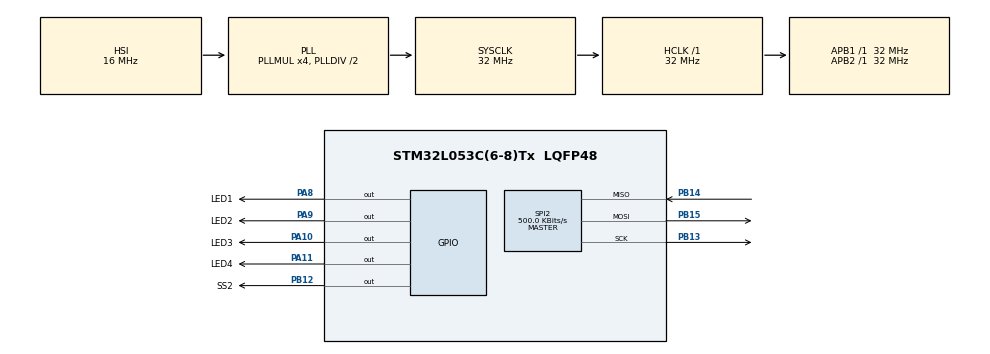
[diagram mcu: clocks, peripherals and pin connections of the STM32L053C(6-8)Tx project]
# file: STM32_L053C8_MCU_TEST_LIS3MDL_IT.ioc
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Dma.Request0=SPI2_RX
Dma.Request1=SPI2_TX
Dma.SPI2_RX.0.Direction=DMA_PERIPH_TO_MEMORY
Dma.SPI2_RX.0.Instance=DMA1_Channel4
Dma.SPI2_RX.0.MemDataAlignment=DMA_MDATAALIGN_BYTE
Dma.SPI2_RX.0.MemInc=DMA_MINC_ENABLE
Dma.SPI2_RX.0.Mode=DMA_NORMAL
Dma.SPI2_RX.0.PeriphDataAlignment=DMA_PDATAALIGN_BYTE
Dma.SPI2_RX.0.PeriphInc=DMA_PINC_DISABLE
Dma.SPI2_RX.0.Priority=DMA_PRIORITY_LOW
Dma.SPI2_TX.1.Direction=DMA_MEMORY_TO_PERIPH
Dma.SPI2_TX.1.Instance=DMA1_Channel5
Dma.SPI2_TX.1.MemDataAlignment=DMA_MDATAALIGN_BYTE
Dma.SPI2_TX.1.MemInc=DMA_MINC_ENABLE
Dma.SPI2_TX.1.Mode=DMA_NORMAL
Dma.SPI2_TX.1.PeriphDataAlignment=DMA_PDATAALIGN_BYTE
Dma.SPI2_TX.1.PeriphInc=DMA_PINC_DISABLE
Dma.SPI2_TX.1.Priority=DMA_PRIORITY_LOW
Mcu.Family=STM32L0
Mcu.Name=STM32L053C(6-8)Tx
Mcu.Package=LQFP48
NVIC.DMA1_Channel4_5_6_7_IRQn=true\:0\:0\:false\:false\:true\:false\:true\:true
NVIC.SPI2_IRQn=true\:0\:0\:true\:false\:true\:true\:true\:true
NVIC.TIM6_DAC_IRQn=true\:0\:0\:false\:false\:true\:true\:true\:true
PA10.GPIO_Label=LED3
PA10.Signal=GPIO_Output
PA11.GPIO_Label=LED4
PA11.Signal=GPIO_Output
PA13.Mode=Serial_Wire
PA13.Signal=SYS_SWDIO
PA14.Mode=Serial_Wire
PA14.Signal=SYS_SWCLK
PA8.GPIO_Label=LED1
PA8.Signal=GPIO_Output
PA9.GPIO_Label=LED2
PA9.Signal=GPIO_Output
PB12.GPIO_Label=SS2
PB12.Signal=GPIO_Output
PB13.GPIO_PuPd=GPIO_NOPULL
PB13.Mode=Full_Duplex_Master
PB13.Signal=SPI2_SCK
PB14.GPIO_PuPd=GPIO_NOPULL
PB14.Mode=Full_Duplex_Master
PB14.Signal=SPI2_MISO
PB15.GPIO_PuPd=GPIO_NOPULL
PB15.Mode=Full_Duplex_Master
PB15.Signal=SPI2_MOSI
ProjectManager.HeapSize=0x200
ProjectManager.StackSize=0x400
ProjectManager.TargetToolchain=STM32CubeIDE
RCC.AHBFreq_Value=32000000
RCC.APB1Freq_Value=32000000
RCC.APB1TimFreq_Value=32000000
RCC.APB2Freq_Value=32000000
RCC.APB2TimFreq_Value=32000000
RCC.HCLKFreq_Value=32000000
RCC.HSE_VALUE=8000000
RCC.HSI16_VALUE=16000000
RCC.HSI48_VALUE=48000000
RCC.HSI_VALUE=16000000
RCC.LSE_VALUE=32768
RCC.MSI_VALUE=2097000
RCC.PLLMUL=RCC_PLLMUL_4
RCC.SYSCLKFreq_VALUE=32000000
RCC.SYSCLKSource=RCC_SYSCLKSOURCE_PLLCLK
RCC.VCOOutputFreq_Value=64000000
SPI2.BaudRatePrescaler=SPI_BAUDRATEPRESCALER_64
SPI2.CLKPhase=SPI_PHASE_2EDGE
SPI2.CLKPolarity=SPI_POLARITY_HIGH
SPI2.CalculateBaudRate=500.0 KBits/s
SPI2.DataSize=SPI_DATASIZE_8BIT
SPI2.Direction=SPI_DIRECTION_2LINES
SPI2.Mode=SPI_MODE_MASTER
SPI2.VirtualType=VM_MASTER
TIM6.AutoReloadPreload=TIM_AUTORELOAD_PRELOAD_ENABLE
TIM6.Period=99
TIM6.Prescaler=32
VP_SYS_V_PVD_IN.Mode=Mode_PVD_Int
VP_TIM6_VS_ClockSourceINT.Mode=Enable_Timer
board=custom

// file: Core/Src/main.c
/* USER CODE BEGIN Header */
/**
 ******************************************************************************
 * @file           : main.c
 * @brief          : Main program body
 ******************************************************************************
 * @attention
 *
 * <h2><center>&copy; Copyright (c) 2023 STMicroelectronics.
 * All rights reserved.</center></h2>
 *
 * This software component is licensed by ST under BSD 3-Clause license,
 * the "License"; You may not use this file except in compliance with the
 * License. You may obtain a copy of the License at:
 *                        opensource.org/licenses/BSD-3-Clause
 *
 ******************************************************************************
 */
/* USER CODE END Header */
#include "main.h"

/* USER CODE BEGIN Includes */

#include "User/driver_lis3mdl.h"

/* USER CODE END Includes */

SPI_HandleTypeDef hspi2;
DMA_HandleTypeDef hdma_spi2_rx;
DMA_HandleTypeDef hdma_spi2_tx;

TIM_HandleTypeDef htim6;

/* USER CODE BEGIN PV */
sDriverLis3mdl_SensorData_t mag_sensor_data = { 0 };
/* USER CODE END PV */

void SystemClock_Config(void);
static void MX_GPIO_Init(void);
static void MX_DMA_Init(void);
static void MX_SPI2_Init(void);
static void MX_TIM6_Init(void);

int main(void) {

	/* MCU Configuration--------------------------------------------------------*/

	/* Reset of all peripherals, Initializes the Flash interface and the Systick. */
	HAL_Init();

	/* Configure the system clock */
	SystemClock_Config();

	/* Initialize all configured peripherals */
	MX_GPIO_Init();
	MX_DMA_Init();
	MX_SPI2_Init();
	MX_TIM6_Init();
	/* USER CODE BEGIN 2 */
	Driver_Lis3mdl_Init(&hspi2);
	/* USER CODE END 2 */

	/* Infinite loop */
	/* USER CODE BEGIN WHILE */
	while (1) {
		HAL_Delay(10);

		/* BLOCKING DRIVER */
		if (Driver_Lis3mdl_ReadSensorData(&hspi2, &mag_sensor_data) == true) {
			Driver_Lis3mdl_ExampleApp(&mag_sensor_data);
		}

		/* NON-BLOCKING DRIVER */
//		if (Driver_Lis3mdl_UpdateSensorData_IT(&hspi2) == true) {
//			mag_sensor_data = Driver_Lis3mdl_GetSensorData();
//			Driver_Lis3mdl_ExampleApp(&mag_sensor_data);
//		}

		/* USER CODE END WHILE */

	}
}

void SystemClock_Config(void) {
	RCC_OscInitTypeDef RCC_OscInitStruct = { 0 };
	RCC_ClkInitTypeDef RCC_ClkInitStruct = { 0 };

	/** Configure the main internal regulator output voltage
	 */
	__HAL_PWR_VOLTAGESCALING_CONFIG(PWR_REGULATOR_VOLTAGE_SCALE1);
	/** Initializes the RCC Oscillators according to the specified parameters
	 * in the RCC_OscInitTypeDef structure.
	 */
	RCC_OscInitStruct.OscillatorType = RCC_OSCILLATORTYPE_HSI;
	RCC_OscInitStruct.HSIState = RCC_HSI_ON;
	RCC_OscInitStruct.HSICalibrationValue = RCC_HSICALIBRATION_DEFAULT;
	RCC_OscInitStruct.PLL.PLLState = RCC_PLL_ON;
	RCC_OscInitStruct.PLL.PLLSource = RCC_PLLSOURCE_HSI;
	RCC_OscInitStruct.PLL.PLLMUL = RCC_PLLMUL_4;
	RCC_OscInitStruct.PLL.PLLDIV = RCC_PLLDIV_2;
	if (HAL_RCC_OscConfig(&RCC_OscInitStruct) != HAL_OK) {
		Error_Handler();
	}
	/** Initializes the CPU, AHB and APB buses clocks
	 */
	RCC_ClkInitStruct.ClockType = RCC_CLOCKTYPE_HCLK | RCC_CLOCKTYPE_SYSCLK | RCC_CLOCKTYPE_PCLK1 | RCC_CLOCKTYPE_PCLK2;
	RCC_ClkInitStruct.SYSCLKSource = RCC_SYSCLKSOURCE_PLLCLK;
	RCC_ClkInitStruct.AHBCLKDivider = RCC_SYSCLK_DIV1;
	RCC_ClkInitStruct.APB1CLKDivider = RCC_HCLK_DIV1;
	RCC_ClkInitStruct.APB2CLKDivider = RCC_HCLK_DIV1;

	if (HAL_RCC_ClockConfig(&RCC_ClkInitStruct, FLASH_LATENCY_1) != HAL_OK) {
		Error_Handler();
	}
}

static void MX_SPI2_Init(void) {

	/* SPI2 parameter configuration*/
	hspi2.Instance = SPI2;
	hspi2.Init.Mode = SPI_MODE_MASTER;
	hspi2.Init.Direction = SPI_DIRECTION_2LINES;
	hspi2.Init.DataSize = SPI_DATASIZE_8BIT;
	hspi2.Init.CLKPolarity = SPI_POLARITY_HIGH;
	hspi2.Init.CLKPhase = SPI_PHASE_2EDGE;
	hspi2.Init.NSS = SPI_NSS_SOFT;
	hspi2.Init.BaudRatePrescaler = SPI_BAUDRATEPRESCALER_64;
	hspi2.Init.FirstBit = SPI_FIRSTBIT_MSB;
	hspi2.Init.TIMode = SPI_TIMODE_DISABLE;
	hspi2.Init.CRCCalculation = SPI_CRCCALCULATION_DISABLE;
	hspi2.Init.CRCPolynomial = 7;
	if (HAL_SPI_Init(&hspi2) != HAL_OK) {
		Error_Handler();
	}

}

static void MX_TIM6_Init(void) {

	TIM_MasterConfigTypeDef sMasterConfig = { 0 };

	htim6.Instance = TIM6;
	htim6.Init.Prescaler = 32;
	htim6.Init.CounterMode = TIM_COUNTERMODE_UP;
	htim6.Init.Period = 99;
	htim6.Init.AutoReloadPreload = TIM_AUTORELOAD_PRELOAD_ENABLE;
	if (HAL_TIM_Base_Init(&htim6) != HAL_OK) {
		Error_Handler();
	}
	sMasterConfig.MasterOutputTrigger = TIM_TRGO_RESET;
	sMasterConfig.MasterSlaveMode = TIM_MASTERSLAVEMODE_DISABLE;
	if (HAL_TIMEx_MasterConfigSynchronization(&htim6, &sMasterConfig) != HAL_OK) {
		Error_Handler();
	}

}

static void MX_DMA_Init(void) {

	/* DMA controller clock enable */
	__HAL_RCC_DMA1_CLK_ENABLE();

	/* DMA interrupt init */
	/* DMA1_Channel4_5_6_7_IRQn interrupt configuration */
	HAL_NVIC_SetPriority(DMA1_Channel4_5_6_7_IRQn, 0, 0);
	HAL_NVIC_EnableIRQ(DMA1_Channel4_5_6_7_IRQn);

}

static void MX_GPIO_Init(void) {
	GPIO_InitTypeDef GPIO_InitStruct = { 0 };

	/* GPIO Ports Clock Enable */
	__HAL_RCC_GPIOB_CLK_ENABLE();
	__HAL_RCC_GPIOA_CLK_ENABLE();

	/*Configure GPIO pin Output Level */
	HAL_GPIO_WritePin(SS2_GPIO_Port, SS2_Pin, GPIO_PIN_RESET);

	/*Configure GPIO pin Output Level */
	HAL_GPIO_WritePin(GPIOA, LED1_Pin | LED2_Pin | LED3_Pin | LED4_Pin, GPIO_PIN_RESET);

	/*Configure GPIO pin : SS2_Pin */
	GPIO_InitStruct.Pin = SS2_Pin;
	GPIO_InitStruct.Mode = GPIO_MODE_OUTPUT_PP;
	GPIO_InitStruct.Pull = GPIO_NOPULL;
	GPIO_InitStruct.Speed = GPIO_SPEED_FREQ_LOW;
	HAL_GPIO_Init(SS2_GPIO_Port, &GPIO_InitStruct);

	/*Configure GPIO pins : LED1_Pin LED2_Pin LED3_Pin LED4_Pin */
	GPIO_InitStruct.Pin = LED1_Pin | LED2_Pin | LED3_Pin | LED4_Pin;
	GPIO_InitStruct.Mode = GPIO_MODE_OUTPUT_PP;
	GPIO_InitStruct.Pull = GPIO_NOPULL;
	GPIO_InitStruct.Speed = GPIO_SPEED_FREQ_LOW;
	HAL_GPIO_Init(GPIOA, &GPIO_InitStruct);

}

void Error_Handler(void) {
	__disable_irq();
	while (1) {
	}
}

/************************ (C) COPYRIGHT STMicroelectronics *****END OF FILE****/
